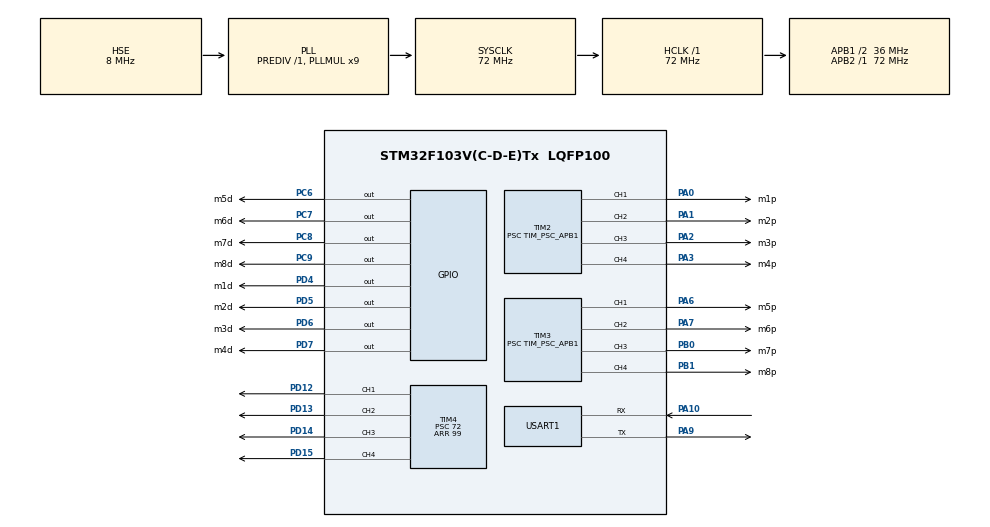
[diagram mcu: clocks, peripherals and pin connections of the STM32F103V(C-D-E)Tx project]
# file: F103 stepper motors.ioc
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Dma.Request0=USART1_RX
Dma.USART1_RX.0.Direction=DMA_PERIPH_TO_MEMORY
Dma.USART1_RX.0.Instance=DMA1_Channel5
Dma.USART1_RX.0.MemDataAlignment=DMA_MDATAALIGN_BYTE
Dma.USART1_RX.0.MemInc=DMA_MINC_ENABLE
Dma.USART1_RX.0.Mode=DMA_NORMAL
Dma.USART1_RX.0.PeriphDataAlignment=DMA_PDATAALIGN_BYTE
Dma.USART1_RX.0.PeriphInc=DMA_PINC_DISABLE
Dma.USART1_RX.0.Priority=DMA_PRIORITY_LOW
IWDG.Prescaler=IWDG_PRESCALER_16
IWDG.Reload=1250
Mcu.Family=STM32F1
Mcu.Name=STM32F103V(C-D-E)Tx
Mcu.Package=LQFP100
Mcu.UserConstants=APB2_TIMER_CLOCKS,72000000;PWM_FREQUENCE,8000;PWM_DEFAULT_DUTY,50;TIM_PSC_APB1,((APB1_TIMER_CLOCKS/PWM_FREQUENCE)/PWM_RESOLUTION -1);PWM_RESOLUTION,100;TIM_PSC_APB2,((APB2_TIMER_CLOCKS/PWM_FREQUENCE)/PWM_RESOLUTION -1);APB1_TIMER_CLOCKS,72000000
NVIC.DMA1_Channel5_IRQn=true\:0\:0\:false\:false\:true\:false\:true\:true
NVIC.PriorityGroup=NVIC_PRIORITYGROUP_4
NVIC.RCC_IRQn=true\:0\:0\:false\:false\:true\:true\:false\:true
NVIC.TIM2_IRQn=true\:0\:0\:false\:false\:true\:true\:true\:true
NVIC.TIM3_IRQn=true\:0\:0\:false\:false\:true\:true\:true\:true
NVIC.USART1_IRQn=true\:0\:0\:false\:false\:true\:true\:true\:true
OSC_IN.Mode=HSE-External-Oscillator
OSC_IN.Signal=RCC_OSC_IN
OSC_OUT.Mode=HSE-External-Oscillator
OSC_OUT.Signal=RCC_OSC_OUT
PA0-WKUP.GPIO_Label=m1p
PA0-WKUP.Signal=S_TIM2_CH1_ETR
PA1.GPIO_Label=m2p
PA1.Signal=S_TIM2_CH2
PA10.Mode=Asynchronous
PA10.Signal=USART1_RX
PA13.Mode=Serial_Wire
PA13.Signal=SYS_JTMS-SWDIO
PA14.Mode=Serial_Wire
PA14.Signal=SYS_JTCK-SWCLK
PA2.GPIO_Label=m3p
PA2.Signal=S_TIM2_CH3
PA3.GPIO_Label=m4p
PA3.Signal=S_TIM2_CH4
PA6.GPIO_Label=m5p
PA6.Signal=S_TIM3_CH1
PA7.GPIO_Label=m6p
PA7.Signal=S_TIM3_CH2
PA9.Mode=Asynchronous
PA9.Signal=USART1_TX
PB0.GPIO_Label=m7p
PB0.Signal=S_TIM3_CH3
PB1.GPIO_Label=m8p
PB1.Signal=S_TIM3_CH4
PC6.GPIO_Label=m5d
PC6.Signal=GPIO_Output
PC7.GPIO_Label=m6d
PC7.Signal=GPIO_Output
PC8.GPIO_Label=m7d
PC8.Signal=GPIO_Output
PC9.GPIO_Label=m8d
PC9.Signal=GPIO_Output
PD12.Signal=S_TIM4_CH1
PD13.Signal=S_TIM4_CH2
PD14.Signal=S_TIM4_CH3
PD15.Signal=S_TIM4_CH4
PD4.GPIO_Label=m1d
PD4.Signal=GPIO_Output
PD5.GPIO_Label=m2d
PD5.Signal=GPIO_Output
PD6.GPIO_Label=m3d
PD6.Signal=GPIO_Output
PD7.GPIO_Label=m4d
PD7.Signal=GPIO_Output
ProjectManager.HeapSize=0x200
ProjectManager.StackSize=0x400
ProjectManager.TargetToolchain=MDK-ARM V5.32
RCC.AHBFreq_Value=72000000
RCC.APB1CLKDivider=RCC_HCLK_DIV2
RCC.APB1Freq_Value=36000000
RCC.APB1TimFreq_Value=72000000
RCC.APB2Freq_Value=72000000
RCC.APB2TimFreq_Value=72000000
RCC.HCLKFreq_Value=72000000
RCC.PLLMUL=RCC_PLL_MUL9
RCC.PLLSourceVirtual=RCC_PLLSOURCE_HSE
RCC.SYSCLKFreq_VALUE=72000000
RCC.SYSCLKSource=RCC_SYSCLKSOURCE_PLLCLK
RCC.USBFreq_Value=72000000
SH.S_TIM2_CH1_ETR.0=TIM2_CH1,PWM Generation1 CH1
SH.S_TIM2_CH2.0=TIM2_CH2,PWM Generation2 CH2
SH.S_TIM2_CH3.0=TIM2_CH3,PWM Generation3 CH3
SH.S_TIM2_CH4.0=TIM2_CH4,PWM Generation4 CH4
SH.S_TIM3_CH1.0=TIM3_CH1,PWM Generation1 CH1
SH.S_TIM3_CH2.0=TIM3_CH2,PWM Generation2 CH2
SH.S_TIM3_CH3.0=TIM3_CH3,PWM Generation3 CH3
SH.S_TIM3_CH4.0=TIM3_CH4,PWM Generation4 CH4
SH.S_TIM4_CH1.0=TIM4_CH1,PWM Generation1 CH1
SH.S_TIM4_CH2.0=TIM4_CH2,PWM Generation2 CH2
SH.S_TIM4_CH3.0=TIM4_CH3,PWM Generation3 CH3
SH.S_TIM4_CH4.0=TIM4_CH4,PWM Generation4 CH4
TIM2.AutoReloadPreload=TIM_AUTORELOAD_PRELOAD_ENABLE
TIM2.Channel-PWM\ Generation1\ CH1=TIM_CHANNEL_1
TIM2.Channel-PWM\ Generation2\ CH2=TIM_CHANNEL_2
TIM2.Channel-PWM\ Generation3\ CH3=TIM_CHANNEL_3
TIM2.Channel-PWM\ Generation4\ CH4=TIM_CHANNEL_4
TIM2.Period=PWM_RESOLUTION-1
TIM2.Prescaler=TIM_PSC_APB1
TIM2.Pulse-PWM\ Generation1\ CH1=PWM_DEFAULT_DUTY
TIM2.Pulse-PWM\ Generation2\ CH2=PWM_DEFAULT_DUTY
TIM2.Pulse-PWM\ Generation3\ CH3=PWM_DEFAULT_DUTY
TIM2.Pulse-PWM\ Generation4\ CH4=PWM_DEFAULT_DUTY
TIM3.AutoReloadPreload=TIM_AUTORELOAD_PRELOAD_ENABLE
TIM3.Channel-PWM\ Generation1\ CH1=TIM_CHANNEL_1
TIM3.Channel-PWM\ Generation2\ CH2=TIM_CHANNEL_2
TIM3.Channel-PWM\ Generation3\ CH3=TIM_CHANNEL_3
TIM3.Channel-PWM\ Generation4\ CH4=TIM_CHANNEL_4
TIM3.Period=PWM_RESOLUTION-1
TIM3.Prescaler=TIM_PSC_APB1
TIM3.Pulse-PWM\ Generation1\ CH1=PWM_DEFAULT_DUTY
TIM3.Pulse-PWM\ Generation2\ CH2=PWM_DEFAULT_DUTY
TIM3.Pulse-PWM\ Generation3\ CH3=PWM_DEFAULT_DUTY
TIM3.Pulse-PWM\ Generation4\ CH4=PWM_DEFAULT_DUTY
TIM4.Channel-PWM\ Generation1\ CH1=TIM_CHANNEL_1
TIM4.Channel-PWM\ Generation2\ CH2=TIM_CHANNEL_2
TIM4.Channel-PWM\ Generation3\ CH3=TIM_CHANNEL_3
TIM4.Channel-PWM\ Generation4\ CH4=TIM_CHANNEL_4
TIM4.Period=99
TIM4.Prescaler=72
TIM4.Pulse-PWM\ Generation1\ CH1=50
TIM4.Pulse-PWM\ Generation2\ CH2=50
TIM4.Pulse-PWM\ Generation3\ CH3=50
TIM4.Pulse-PWM\ Generation4\ CH4=50
USART1.VirtualMode=VM_ASYNC
VP_IWDG_VS_IWDG.Mode=IWDG_Activate
VP_TIM2_VS_ClockSourceINT.Mode=Internal
VP_TIM3_VS_ClockSourceINT.Mode=Internal
VP_TIM4_VS_ClockSourceINT.Mode=Internal
board=custom

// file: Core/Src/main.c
/* USER CODE BEGIN Header */
/**
  ******************************************************************************
  * @file           : main.c
  * @brief          : Main program body
  ******************************************************************************
  * @attention
  *
  * Copyright (c) 2023 STMicroelectronics.
  * All rights reserved.
  *
  * This software is licensed under terms that can be found in the LICENSE file
  * in the root directory of this software component.
  * If no LICENSE file comes with this software, it is provided AS-IS.
  *
  ******************************************************************************
  */
/* USER CODE END Header */
#include "main.h"
#include "dma.h"
#include "iwdg.h"
#include "tim.h"
#include "usart.h"
#include "gpio.h"

/* USER CODE BEGIN Includes */
#include "Y_Step_Motor.h"
#include "MotorControl.h"
#include "usart1Dma.h"
#include "Receive_execute.h"
#include<stdio.h>
#include<string.h>
/* USER CODE END Includes */

void SystemClock_Config(void);

int main(void)
{

  /* MCU Configuration--------------------------------------------------------*/

  /* Reset of all peripherals, Initializes the Flash interface and the Systick. */
  HAL_Init();

  /* Configure the system clock */
  SystemClock_Config();

  /* Initialize all configured peripherals */
  MX_GPIO_Init();
  MX_DMA_Init();
  MX_TIM2_Init();
  MX_USART1_UART_Init();
  MX_TIM3_Init();
  MX_IWDG_Init();
  MX_TIM4_Init();
  /* USER CODE BEGIN 2 */
 // EnableUsart_It();
 //HAL_TIM_PWM_Start(&htim3,TIM_CHANNEL_1);
  /* USER CODE END 2 */

  /* Infinite loop */
  while (1)
  {

    /* USER CODE BEGIN 3 */
	 // 	judge_execute();
	  motor7_descent();
	HAL_Delay(3000);
  }
  /* USER CODE END 3 */
}

void SystemClock_Config(void)
{
  RCC_OscInitTypeDef RCC_OscInitStruct = {0};
  RCC_ClkInitTypeDef RCC_ClkInitStruct = {0};

  /** Initializes the RCC Oscillators according to the specified parameters
  * in the RCC_OscInitTypeDef structure.
  */
  RCC_OscInitStruct.OscillatorType = RCC_OSCILLATORTYPE_LSI|RCC_OSCILLATORTYPE_HSE;
  RCC_OscInitStruct.HSEState = RCC_HSE_ON;
  RCC_OscInitStruct.HSEPredivValue = RCC_HSE_PREDIV_DIV1;
  RCC_OscInitStruct.HSIState = RCC_HSI_ON;
  RCC_OscInitStruct.LSIState = RCC_LSI_ON;
  RCC_OscInitStruct.PLL.PLLState = RCC_PLL_ON;
  RCC_OscInitStruct.PLL.PLLSource = RCC_PLLSOURCE_HSE;
  RCC_OscInitStruct.PLL.PLLMUL = RCC_PLL_MUL9;
  if (HAL_RCC_OscConfig(&RCC_OscInitStruct) != HAL_OK)
  {
    Error_Handler();
  }

  /** Initializes the CPU, AHB and APB buses clocks
  */
  RCC_ClkInitStruct.ClockType = RCC_CLOCKTYPE_HCLK|RCC_CLOCKTYPE_SYSCLK
                              |RCC_CLOCKTYPE_PCLK1|RCC_CLOCKTYPE_PCLK2;
  RCC_ClkInitStruct.SYSCLKSource = RCC_SYSCLKSOURCE_PLLCLK;
  RCC_ClkInitStruct.AHBCLKDivider = RCC_SYSCLK_DIV1;
  RCC_ClkInitStruct.APB1CLKDivider = RCC_HCLK_DIV2;
  RCC_ClkInitStruct.APB2CLKDivider = RCC_HCLK_DIV1;

  if (HAL_RCC_ClockConfig(&RCC_ClkInitStruct, FLASH_LATENCY_2) != HAL_OK)
  {
    Error_Handler();
  }
}

void Error_Handler(void)
{
  __disable_irq();
  while (1)
  {
  }
}
